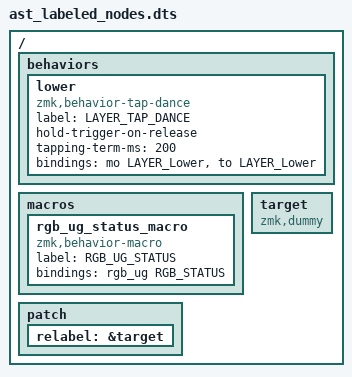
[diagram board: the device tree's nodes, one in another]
/ {
    behaviors {
        // For the "layer" key, it'd nice to be able to use it as either a shift or a toggle.
        // Configure it as a tap dance, so the first tap (or hold) is a &mo and the second tap is a &to
        lower: lower {
            compatible = "zmk,behavior-tap-dance";
            label = "LAYER_TAP_DANCE";
            #binding-cells = <0>;
            hold-trigger-on-release;
            tapping-term-ms = <200>;
            bindings = <&mo LAYER_Lower>, <&to LAYER_Lower>;
        };
    };
};

/ {
    macros {
        rgb_ug_status_macro: rgb_ug_status_macro {
            label = "RGB_UG_STATUS";
            compatible = "zmk,behavior-macro";
            #binding-cells = <0>;
            bindings = <&rgb_ug RGB_STATUS>;
        };
    };
};

/ {
    target: target {
        compatible = "zmk,dummy";
    };

    patch {
        relabel: &target {};
    };
};
